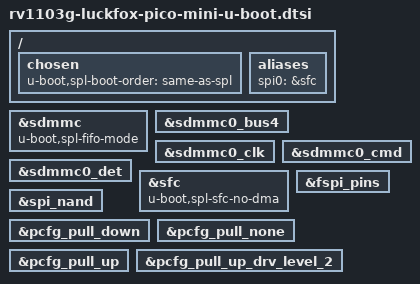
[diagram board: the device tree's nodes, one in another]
// SPDX-License-Identifier: GPL-2.0+

#include "rv1103g-u-boot.dtsi"

/ {
	chosen {
		u-boot,spl-boot-order = "same-as-spl", &sdmmc, &spi_nand;
	};

	aliases {
		spi0 = &sfc;
	};
};

&sdmmc {
	bootph-pre-ram;
	bootph-some-ram;
	u-boot,spl-fifo-mode;
};

&sdmmc0_bus4 {
	bootph-pre-ram;
	bootph-some-ram;
};

&sdmmc0_clk {
	bootph-pre-ram;
	bootph-some-ram;
};

&sdmmc0_cmd {
	bootph-pre-ram;
	bootph-some-ram;
};

&sdmmc0_det {
	bootph-pre-ram;
	bootph-some-ram;
};

&sfc {
	u-boot,spl-sfc-no-dma;
};

&fspi_pins {
	bootph-pre-ram;
	bootph-some-ram;
};

&spi_nand {
	bootph-all;
};

&pcfg_pull_down {
	bootph-all;
};

&pcfg_pull_none {
	bootph-all;
};

&pcfg_pull_up {
	bootph-all;
};

&pcfg_pull_up_drv_level_2 {
	bootph-pre-ram;
	bootph-some-ram;
};
